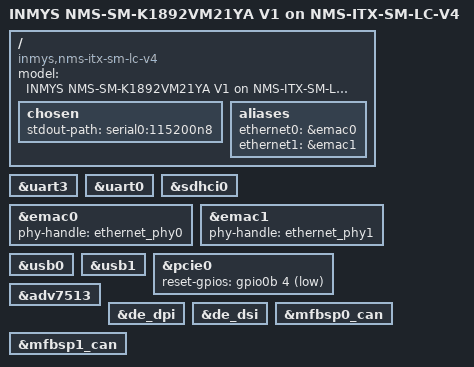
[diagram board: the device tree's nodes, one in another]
// SPDX-License-Identifier: GPL-2.0+
/*
 * NMS-ITX-SM-LC-V4 - mini-ITX SMARC carrier
 *
 * The carrier provides: 2 x GbE, HDMI, DP (via DP-to-VGA), DSI/LVDS,
 * M.2 SATA, CAN (buffered to UART), I2S audio, fan control, I2C GPIO
 * expander and an EEPROM with the carrier ID.
 *
 * Only the bring-up relevant part is described here; the rest is added
 * as it gets validated on hardware.
 *
 * Copyright (C) 2026 INMYS
 */

/dts-v1/;

#include <dt-bindings/gpio/gpio.h>

#include "nms-sm-k1892vm21ya.dtsi"

/ {
	model = "INMYS NMS-SM-K1892VM21YA V1 on NMS-ITX-SM-LC-V4";
	compatible = "inmys,nms-itx-sm-lc-v4",
		     "inmys,nms-sm-k1892vm21ya",
		     "inmys,nms-sm-k1892",
		     "elvees,mcom03r";

	chosen {
		stdout-path = "serial0:115200n8";
	};

	aliases {
		ethernet0 = &emac0;
		ethernet1 = &emac1;
	};
};

/* SER0 console header */
&uart3 {
	status = "okay";
};

&uart0 {
	status = "okay";
};

/* SD card slot */
&sdhci0 {
	status = "okay";
};

/* 2 x GbE */
&emac0 {
	status = "okay";
	phy-handle = <&ethernet_phy0>;
};

&emac1 {
	status = "okay";
	phy-handle = <&ethernet_phy1>;
};

/* USB */
&usb0 {
	status = "okay";
};

&usb1 {
	status = "okay";
};

/* PCIe / M.2 SATA */
&pcie0 {
	status = "okay";
	reset-gpios = <&gpio0b 4 GPIO_ACTIVE_LOW>;
};

/* HDMI */
&adv7513 {
	status = "okay";
};

&de_dpi {
	status = "okay";
};

/* DSI -> LVDS panel */
&de_dsi {
	status = "okay";
};

/* CAN (buffered) */
&mfbsp0_can {
	status = "okay";
};

&mfbsp1_can {
	status = "okay";
};
